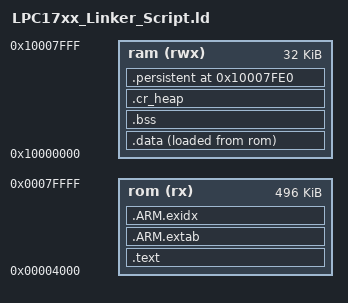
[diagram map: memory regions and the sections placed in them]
/* Linker script for Cortex-M3
 *
 * Version:CodeSourcery Sourcery G++ Lite 2007q3-53
 * BugURL:https://support.codesourcery.com/GNUToolchain/
 *
 *  Copyright 2007 CodeSourcery.
 *
 * The authors hereby grant permission to use, copy, modify, distribute,
 * and license this software and its documentation for any purpose, provided
 * that existing copyright notices are retained in all copies and that this
 * notice is included verbatim in any distributions. No written agreement,
 * license, or royalty fee is required for any of the authorized uses.
 * Modifications to this software may be copyrighted by their authors
 * and need not follow the licensing terms described here, provided that
 * the new terms are clearly indicated on the first page of each file where
 * they apply. */

OUTPUT_FORMAT ("elf32-littlearm", "elf32-bigarm", "elf32-littlearm")
ENTRY(_start)
SEARCH_DIR(.)
GROUP(-lgcc -lc -lcs3 -lcs3unhosted -lcs3micro)

MEMORY
{
  rom (rx)  : ORIGIN = 0x00004000, LENGTH = (512K - 16384)
  ram (rwx) : ORIGIN = 0x10000000, LENGTH =  32K
}

EXTERN(Reset_Handler)
ENTRY(Reset_Handler)

SECTIONS
{
	.text :
	{
		. = ALIGN(0x400); /* Ensure that vector table is aligned as hardware requires. */
		_interrupt_vector_table = .;
		KEEP(*(.irq_handler_table))

		*(.text .text.* .gnu.linkonce.t.*)
		*(.rodata .rodata.* .gnu.linkonce.r.*)

		*(.eh_frame_hdr)
		*(.eh_frame)

		. = ALIGN(4);
		KEEP(*(.init))

		. = ALIGN(4);
		__preinit_array_start = .;
		KEEP (*(.preinit_array))
		__preinit_array_end = .;

		. = ALIGN(4);
		__init_array_start = .;
		KEEP (*(SORT(.init_array.*)))
		KEEP (*(.init_array))
		__init_array_end = .;

		. = ALIGN(0x4);
		KEEP (*crtbegin.o(.ctors))
		KEEP (*(EXCLUDE_FILE (*crtend.o) .ctors))
		KEEP (*(SORT(.ctors.*)))
		KEEP (*crtend.o(.ctors))

		. = ALIGN(4);
		KEEP(*(.fini))

		. = ALIGN(4);
		__fini_array_start = .;
		KEEP (*(.fini_array))
		KEEP (*(SORT(.fini_array.*)))
		__fini_array_end = .;

		KEEP (*crtbegin.o(.dtors))
		KEEP (*(EXCLUDE_FILE (*crtend.o) .dtors))
		KEEP (*(SORT(.dtors.*)))
		KEEP (*crtend.o(.dtors))

		. = ALIGN(8);
		_etext = .;

	} > rom


	.ARM.extab : 
	{
		*(.ARM.extab* .gnu.linkonce.armextab.*)
	} > rom

	__exidx_start = .;
	.ARM.exidx :
	{
		*(.ARM.exidx* .gnu.linkonce.armexidx.*)
	} > rom
	__exidx_end = .;

	_etext = .;

	.data :
	{
		_data = .;
		*(vtable)
		*(.data*)
		_edata = .;
	} > ram AT>rom

	/* zero initialized data */
	.bss :
	{
		_bss = .;
		*(.bss*)
		*(COMMON)
		_ebss = .;
	} > ram

	/* Where we put the heap with cr_clib */
	.cr_heap :
	{
		end = .;
		_pvHeapStart = .;
	} > ram

	. = ORIGIN(ram) + LENGTH(ram) - 32;
	_StackTop = .;

	.persistent :
	{
		LONG(0);
		LONG(0);
		LONG(0);
		LONG(0);
		LONG(0);
		LONG(0);
		LONG(0);
		bootloader_ctrl = .;
		LONG(0);
	} > ram

}
